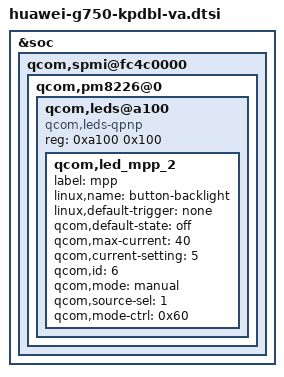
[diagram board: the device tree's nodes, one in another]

&soc {
	qcom,spmi@fc4c0000{
		qcom,pm8226@0{

			qcom,leds@a100{
				compatible = "qcom,leds-qpnp";
				reg = <0xa100 0x100>;
				status = "okay";
				qcom,led_mpp_2 {
					label = "mpp";
					linux,name = "button-backlight";
					linux,default-trigger = "none";
					qcom,default-state = "off";
					qcom,max-current = <40>;
					qcom,current-setting = <5>;
					qcom,id = <6>;
					qcom,mode = "manual";
					qcom,source-sel = <1>;
					qcom,mode-ctrl = <0x60>;
				};
			};
		};
	};	
};
